# S32K324_M7 register map
Vendor: NXP Semiconductors; File version: 1.1
CPU: CM7 r0p1, little endian, MPU, FPU, VTOR, 4 interrupt priority bits
Registers are 32-bit, read-write, reset 0x0 unless marked. A register's access mark holds for its fields unless they carry their own. Offsets are from the block's base; [hi:lo] are bit positions; {n}, {i} and the like mark numbered series; 'fields as' and 'values as' point back to an identical list.

## CAN_0 — CAN
Base 0x40304000
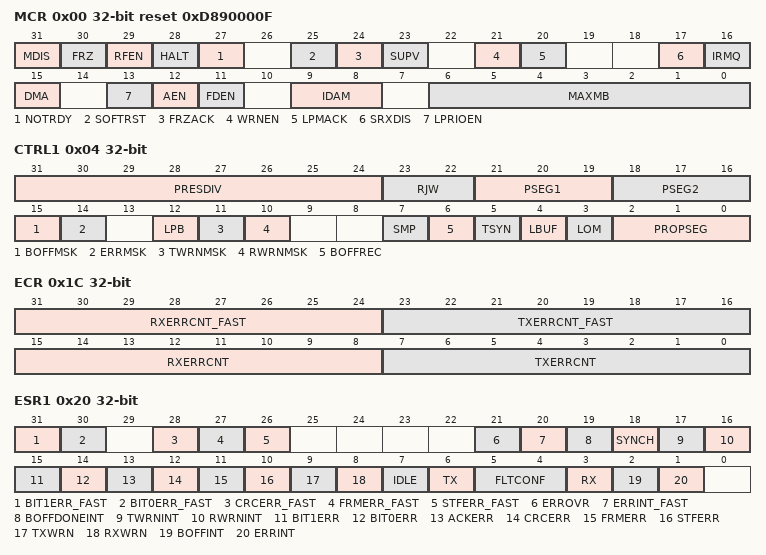
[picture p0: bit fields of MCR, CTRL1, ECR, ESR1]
0x00 MCR reset 0xD890000F — Module Configuration Register
  [31] MDIS — Module Disable
    0=flexcan_enabled (Enable the FlexCAN module.); 1=flexcan_disabled (Disable the FlexCAN module.)
  [30] FRZ — Freeze Enable
    0=freeze_mode_disabled (Not enabled to enter Freeze mode.); 1=freeze_mode_enabled (Enabled to enter Freeze mode.)
  [29] RFEN — Legacy Rx FIFO Enable
    0=id1 (Legacy Rx FIFO not enabled.); 1=id3 (Legacy Rx FIFO enabled.)
  [28] HALT — Halt FlexCAN
    0=HALT_disable (No Freeze mode request.); 1=HALT_enable (Enters Freeze mode if the FRZ bit is asserted.)
  [27] NOTRDY ro — FlexCAN Not Ready
    0=id1 (FlexCAN module is either in Normal mode, Listen-Only mode, or Loop-Back mode.); 1=id5 (FlexCAN module is either in Disable mode or Freeze mode.)
  [25] SOFTRST — Soft Reset
    0=SOFTRST_no_reset_request (No reset request.); 1=SOFTRST_reset_registers (Resets the registers affected by soft reset.)
  [24] FRZACK ro — Freeze Mode Acknowledge
    0=freeze_mode_no (FlexCAN not in Freeze mode, prescaler running.); 1=freeze_mode_yes (FlexCAN in Freeze mode, prescaler stopped.)
  [23] SUPV — Supervisor Mode
    0=id2 (FlexCAN is in User mode. Affected registers allow both Supervisor and Unrestricted accesses.); 1=id4 (FlexCAN is in Supervisor mode. Affected registers allow only Supervisor access. Unrestricted access behaves as though the access was done to an unimplemented register location.)
  [21] WRNEN — Warning Interrupt Enable
    0=TWRNINT_RWRNINT_inactive (TWRNINT and RWRNINT bits are zero, independent of the values in the error counters.); 1=TWRNINT_RWRNINT_active (TWRNINT and RWRNINT bits are set when the respective error counter transitions from less than 96 to greater than or equal to 96.)
  [20] LPMACK ro — Low-Power Mode Acknowledge
    0=low_power_no (FlexCAN is not in a low-power mode.); 1=low_power_yes (FlexCAN is in a low-power mode.)
  [17] SRXDIS — Self Reception Disable
    0=self_reception_enabled; 1=self_reception_disabled
  [16] IRMQ — Individual Rx Masking And Queue Enable
    0=individual_rx_masking_disabled (Individual Rx masking and queue feature are disabled. For backward compatibility with legacy applications, the reading of C/S word locks the MB even if it is EMPTY.); 1=individual_rx_masking_enabled (Individual Rx masking and queue feature are enabled.)
  [15] DMA — DMA Enable
    0=id1 (DMA feature for Legacy RX FIFO or Enhanced Rx FIFO disabled.); 1=id3 (DMA feature for Legacy RX FIFO or Enhanced Rx FIFO enabled.)
  [13] LPRIOEN — Local Priority Enable
    0=local_priority_disabled; 1=local_priority_enabled
  [12] AEN — Abort Enable
    0=abort_disabled; 1=abort_enabled
  [11] FDEN — CAN FD operation enable
    0=CAN_FD_disabled (CAN FD is disabled. FlexCAN is able to receive and transmit messages in CAN 2.0 format.); 1=CAN_FD_enabled (CAN FD is enabled. FlexCAN is able to receive and transmit messages in both CAN FD and CAN 2.0 formats.)
  [9:8] IDAM — ID Acceptance Mode
    0=one_full_ID (Format A: One full ID (standard and extended) per ID filter table element.); 1=two_full_ID (Format B: Two full standard IDs or two partial 14-bit (standard and extended) IDs per ID filter table element.); 2=four_partial_ID (Format C: Four partial 8-bit standard IDs per ID filter table element.); 3=all_frames_rejected (Format D: All frames rejected.)
  [6:0] MAXMB — Number Of The Last Message Buffer
0x04 CTRL1 — Control 1 Register
  [31:24] PRESDIV — Prescaler Division Factor
  [23:22] RJW — Resync Jump Width
  [21:19] PSEG1 — Phase Segment 1
  [18:16] PSEG2 — Phase Segment 2
  [15] BOFFMSK — Bus Off Interrupt Mask
    0=bus_off_int_disabled (Bus Off interrupt disabled.); 1=bus_off_int_enabled (Bus Off interrupt enabled.)
  [14] ERRMSK — Error Interrupt Mask
    0=error_int_disabled (Error interrupt disabled.); 1=error_int_enabled (Error interrupt enabled.)
  [12] LPB — Loop Back Mode
    0=loopback_disabled; 1=loopback_enabled
  [11] TWRNMSK — Tx Warning Interrupt Mask
    0=tx_warning_int_disabled (Tx Warning interrupt disabled.); 1=tx_warning_int_enabled (Tx Warning interrupt enabled.)
  [10] RWRNMSK — Rx Warning Interrupt Mask
    0=rx_warning_int_disabled (Rx Warning interrupt disabled.); 1=rx_warning_int_enabled (Rx Warning interrupt enabled.)
  [7] SMP — CAN Bit Sampling
    0=one_sample (Just one sample is used to determine the bit value.); 1=Three samples are used to determine the value of the received bit: the regular one (sample point) and two preceding samples; a majority rule is used
  [6] BOFFREC — Bus Off Recovery
    0=auto_recover_enabled (Automatic recovering from Bus Off state enabled.); 1=auto_recover_disabled (Automatic recovering from Bus Off state disabled.)
  [5] TSYN — Timer Sync
    0=timer_sync_disabled (Timer sync feature disabled); 1=timer_sync_enabled (Timer sync feature enabled)
  [4] LBUF — Lowest Buffer Transmitted First
    0=highest_buffer_first (Buffer with highest priority is transmitted first.); 1=lowest_buffer_first (Lowest number buffer is transmitted first.)
  [3] LOM — Listen-Only Mode
    0=listen_only_mode_disabled (Listen-Only mode is deactivated.); 1=listen_only_mode_enabled (FlexCAN module operates in Listen-Only mode.)
  [2:0] PROPSEG — Propagation Segment
0x08 TIMER — Free Running Timer
  [15:0] TIMER — Timer Value
0x10 RXMGMASK reset not defined — Rx Mailboxes Global Mask Register
  [31:0] MG — Rx Mailboxes Global Mask Bits
0x14 RX14MASK reset not defined
  [31:0] RX14M — Rx Buffer 14 Mask Bits
0x18 RX15MASK reset not defined
  [31:0] RX15M — Rx Buffer 15 Mask Bits
0x1C ECR — Error Counter
  [31:24] RXERRCNT_FAST — Receive Error Counter for fast bits
  [23:16] TXERRCNT_FAST — Transmit Error Counter for fast bits
  [15:8] RXERRCNT — Receive Error Counter
  [7:0] TXERRCNT — Transmit Error Counter
0x20 ESR1 — Error and Status 1 Register
  [31] BIT1ERR_FAST ro — Bit1 Error in the Data Phase of CAN FD frames with the BRS bit set
    0=bit1_error_no (No such occurrence.); 1=bit1_error_yes (At least one bit sent as recessive is received as dominant.)
  [30] BIT0ERR_FAST ro — Bit0 Error in the Data Phase of CAN FD frames with the BRS bit set
    0=bit0_error_no (No such occurrence.); 1=bit0_error_yes (At least one bit sent as dominant is received as recessive.)
  [28] CRCERR_FAST ro — Cyclic Redundancy Check Error in the CRC field of CAN FD frames with the BRS bit set
    0=CRC_error_no (No such occurrence.); 1=CRC_error_yes (A CRC error occurred since last read of this register.)
  [27] FRMERR_FAST ro — Form Error in the Data Phase of CAN FD frames with the BRS bit set
    0=form_error_no (No such occurrence.); 1=form_error_yes (A form error occurred since last read of this register.)
  [26] STFERR_FAST ro — Stuffing Error in the Data Phase of CAN FD frames with the BRS bit set
    0=stuffing_error_no (No such occurrence.); 1=stuffing_error_yes (A stuffing error occurred since last read of this register.)
  [21] ERROVR write-1-clears — Error Overrun
    0=overrun_not_occurred (Overrun has not occurred.); 1=overrun_occurred (Overrun has occurred.)
  [20] ERRINT_FAST write-1-clears — Error interrupt for errors detected in Data Phase of CAN FD frames with BRS bit set
    0=errors_data_phase_no (No such occurrence.); 1=errors_data_phase_yes (Indicates setting of any error bit detected in the data phase of CAN FD frames with the BRS bit set.)
  [19] BOFFDONEINT write-1-clears — Bus Off Done Interrupt
    0=bus_off_not_done (No such occurrence.); 1=bus_off_done (FlexCAN module has completed Bus Off process.)
  [18] SYNCH ro — CAN Synchronization Status
    0=CAN_bus_sync_no (FlexCAN is not synchronized to the CAN bus.); 1=CAN_bus_sync_yes (FlexCAN is synchronized to the CAN bus.)
  [17] TWRNINT write-1-clears — Tx Warning Interrupt Flag
    0=Tx_warning_int_no (No such occurrence.); 1=Tx_warning_int_yes (The Tx error counter transitioned from less than 96 to greater than or equal to 96.)
  [16] RWRNINT write-1-clears — Rx Warning Interrupt Flag
    0=Rx_warning_int_no (No such occurrence.); 1=Rx_warning_int_yes (The Rx error counter transitioned from less than 96 to greater than or equal to 96.)
  [15] BIT1ERR ro — Bit1 Error
    values as BIT1ERR_FAST
  [14] BIT0ERR ro — Bit0 Error
    values as BIT0ERR_FAST
  [13] ACKERR ro — Acknowledge Error
    0=ACK_error_no (No such occurrence.); 1=ACK_error_yes (An ACK error occurred since last read of this register.)
  [12] CRCERR ro — Cyclic Redundancy Check Error
    values as CRCERR_FAST
  [11] FRMERR ro — Form Error
    0=form_error_no (No such occurrence.); 1=form_error_yes (A Form Error occurred since last read of this register.)
  [10] STFERR ro — Stuffing Error
    values as STFERR_FAST
  [9] TXWRN ro — TX Error Warning
    0=TXERRCNT_LT_96 (No such occurrence.); 1=TXERRCNT_GTE_96 (TXERRCNT is greater than or equal to 96.)
  [8] RXWRN ro — Rx Error Warning
    0=RXERRCNT_LT_96 (No such occurrence.); 1=RXERRCNT_GTE_96 (RXERRCNT is greater than or equal to 96.)
  [7] IDLE ro
    0=can_bus_not_idle (No such occurrence.); 1=can_bus_idle (CAN bus is now IDLE.)
  [6] TX ro — FlexCAN In Transmission
    0=transmit_message_no (FlexCAN is not transmitting a message.); 1=transmit_message_yes (FlexCAN is transmitting a message.)
  [5:4] FLTCONF ro — Fault Confinement State
    0=error_active; 1=error_passive; 0b1x=bus_off
  [3] RX ro — FlexCAN In Reception
    0=DISABLE (FlexCAN is not receiving a message.); 1=ENABLE (FlexCAN is receiving a message.)
  [2] BOFFINT write-1-clears — Bus Off Interrupt
    0=DISABLE (No such occurrence.); 1=ENABLE (FlexCAN module entered Bus Off state.)
  [1] ERRINT write-1-clears — Error Interrupt
    0=DISABLE (No such occurrence.); 1=ENABLE (Indicates setting of any error bit in the Error and Status register.)
0x24 IMASK2 — Interrupt Masks 2 Register
  [31:0] BUF63TO32M — Buffer MBi Mask
0x28 IMASK1 — Interrupt Masks 1 Register
  [31:0] BUF31TO0M — Buffer MBi Mask
0x2C IFLAG2 write-1-clears — Interrupt Flags 2 Register
  [31:0] BUF63TO32I write-1-clears — Buffer MBi Interrupt
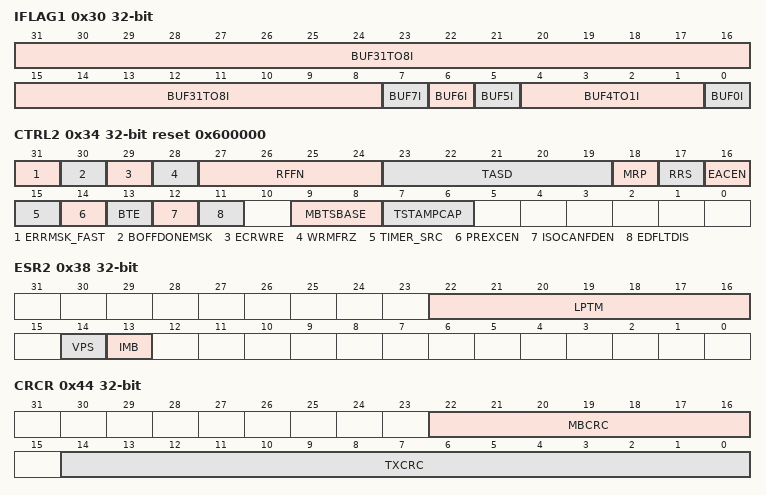
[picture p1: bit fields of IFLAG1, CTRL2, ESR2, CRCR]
0x30 IFLAG1 write-1-clears — Interrupt Flags 1 Register
  [31:8] BUF31TO8I write-1-clears — Buffer MBi Interrupt
  [7] BUF7I write-1-clears — Buffer MB7 Interrupt Or Legacy Rx FIFO Overflow
    0=id1 (No occurrence of MB7 completing transmission/reception when MCR[RFEN]=0, or of Legacy Rx FIFO overflow when MCR[RFEN]=1); 1=id3 (MB7 completed transmission/reception when MCR[RFEN]=0, or Legacy Rx FIFO overflow when MCR[RFEN]=1)
  [6] BUF6I write-1-clears — Buffer MB6 Interrupt Or Legacy Rx FIFO Warning
    0=id1 (No occurrence of MB6 completing transmission/reception when MCR[RFEN]=0, or of Legacy Rx FIFO almost full when MCR[RFEN]=1); 1=id3 (MB6 completed transmission/reception when MCR[RFEN]=0, or Legacy Rx FIFO almost full when MCR[RFEN]=1)
  [5] BUF5I write-1-clears — Buffer MB5 Interrupt Or Frames available in Legacy Rx FIFO
    0=id1 (No occurrence of MB5 completing transmission/reception when MCR[RFEN]=0, or of frame(s) available in the Legacy FIFO, when MCR[RFEN]=1); 1=id3 (MB5 completed transmission/reception when MCR[RFEN]=0, or frame(s) available in the Legacy Rx FIFO when MCR[RFEN]=1. It generates a DMA request in case of MCR[RFEN] and MCR[DMA] are enabled.)
  [4:1] BUF4TO1I write-1-clears — Buffer MBi Interrupt Or Reserved
  [0] BUF0I write-1-clears — Buffer MB0 Interrupt Or Clear Legacy FIFO bit
    0=buffer_Tx_Rx_not_complete (The corresponding buffer has no occurrence of successfully completed transmission or reception when MCR[RFEN]=0.); 1=buffer_Tx_Rx_complete (The corresponding buffer has successfully completed transmission or reception when MCR[RFEN]=0.)
0x34 CTRL2 reset 0x600000 — Control 2 Register
  [31] ERRMSK_FAST — Error Interrupt Mask for errors detected in the data phase of fast CAN FD frames
    0=DISABLE (ERRINT_FAST error interrupt disabled.); 1=ENABLE (ERRINT_FAST error interrupt enabled.)
  [30] BOFFDONEMSK — Bus Off Done Interrupt Mask
    0=DISABLE (Bus off done interrupt disabled.); 1=ENABLE (Bus off done interrupt enabled.)
  [29] ECRWRE — Error-correction Configuration Register Write Enable
    0=DISABLE (Disable update.); 1=ENABLE (Enable update.)
  [28] WRMFRZ — Write-Access To Memory In Freeze Mode
    0=DISABLE (Maintain the write access restrictions.); 1=ENABLE (Enable unrestricted write access to FlexCAN memory.)
  [27:24] RFFN — Number Of Legacy Rx FIFO Filters
  [23:19] TASD — Tx Arbitration Start Delay
  [18] MRP — Mailboxes Reception Priority
    0=id1 (Matching starts from Legacy Rx FIFO or Enhanced Rx FIFO and continues on mailboxes.); 1=id3 (Matching starts from mailboxes and continues on Legacy Rx FIFO or Enhanced Rx FIFO.)
  [17] RRS — Remote Request Storing
    0=remote_response_frame_not_generated (Remote response frame is generated.); 1=remote_response_frame_generated (Remote request frame is stored.)
  [16] EACEN — Entire Frame Arbitration Field Comparison Enable For Rx Mailboxes
    0=RTR_compare_no (Rx mailbox filter's IDE bit is always compared and RTR is never compared despite mask bits.); 1=RTR_compare_yes (Enables the comparison of both Rx mailbox filter's IDE and RTR bit with their corresponding bits within the incoming frame. Mask bits do apply.)
  [15] TIMER_SRC — Timer Source
    0=CAN_bit_clock (The free running timer is clocked by the CAN bit clock, which defines the baud rate on the CAN bus.); 1=external_clock (The free running timer is clocked by an external time tick. The period can be either adjusted to be equal to the baud rate on the CAN bus, or a different value as required. See the device-specific section for details about the external time tick.)
  [14] PREXCEN — Protocol Exception Enable
    0=DISABLE (Protocol exception is disabled.); 1=ENABLE (Protocol exception is enabled.)
  [13] BTE — Bit Timing Expansion enable
    0=DISABLE (CAN Bit timing expansion is disabled.); 1=ENABLE (CAN bit timing expansion is enabled.)
  [12] ISOCANFDEN — ISO CAN FD Enable
    0=non_ISO (FlexCAN operates using the non-ISO CAN FD protocol.); 1=ISO (FlexCAN operates using the ISO CAN FD protocol (ISO 11898-1).)
  [11] EDFLTDIS — Edge Filter Disable
    0=ENABLE (Edge filter is enabled); 1=DISABLE (Edge filter is disabled)
  [9:8] MBTSBASE — Message Buffer Time Stamp Base
    0=base_TIMER (Message buffer time stamp base is TIMER); 1=base_lower_16 (Message buffer time stamp base is lower 16 bits of high resolution timer); 2=base_upper_16 (Message buffer time stamp base is upper 16 bits of high resolution timer)
  [7:6] TSTAMPCAP — Time Stamp Capture Point
    0=time_stamp_capture_disabled (The high resolution time stamp capture is disabled); 1=time_stamp_capture_frame_end_enabled (The high resolution time stamp is captured in the end of the CAN frame); 2=time_stamp_capture_frame_start_enabled (The high resolution time stamp is captured in the start of the CAN frame); 3=time_stamp_capture_2_types_enabled (The high resolution time stamp is captured in the start of frame for classical CAN frames and in res bit for CAN FD frames)
0x38 ESR2 ro — Error and Status 2 Register
  [22:16] LPTM — Lowest Priority Tx Mailbox
  [14] VPS — Valid Priority Status
    0=invalid (Contents of IMB and LPTM are invalid.); 1=valid (Contents of IMB and LPTM are valid.)
  [13] IMB — Inactive Mailbox
    0=inactive_mailbox_no (If ESR2[VPS] is asserted, the ESR2[LPTM] is not an inactive mailbox.); 1=inactive_mailbox_yes (If ESR2[VPS] is asserted, there is at least one inactive mailbox. LPTM content is the number of the first one.)
0x44 CRCR ro — CRC Register
  [22:16] MBCRC — CRC Mailbox
  [14:0] TXCRC — Transmitted CRC value
0x48 RXFGMASK reset not defined — Legacy Rx FIFO Global Mask Register
  [31:0] FGM — Legacy Rx FIFO Global Mask Bits
0x4C RXFIR ro reset not defined — Legacy Rx FIFO Information Register
  [8:0] IDHIT — Identifier Acceptance Filter Hit Indicator
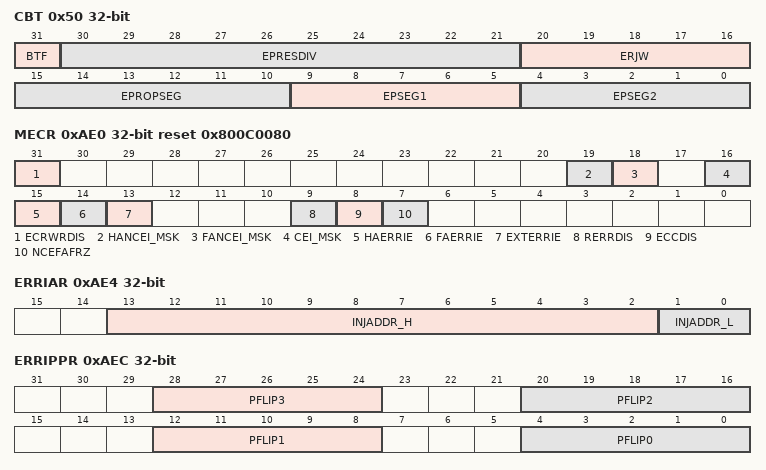
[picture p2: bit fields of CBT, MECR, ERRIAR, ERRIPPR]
0x50 CBT — CAN Bit Timing Register
  [31] BTF — Bit Timing Format Enable
    0=DISABLE (Extended bit time definitions disabled.); 1=ENABLE (Extended bit time definitions enabled.)
  [30:21] EPRESDIV — Extended Prescaler Division Factor
  [20:16] ERJW — Extended Resync Jump Width
  [15:10] EPROPSEG — Extended Propagation Segment
  [9:5] EPSEG1 — Extended Phase Segment 1
  [4:0] EPSEG2 — Extended Phase Segment 2
0x6C IMASK3 — Interrupt Masks 3 Register
  [31:0] BUF95TO64M — Buffer MBi Mask
0x74 IFLAG3 write-1-clears — Interrupt Flags 3 Register
  [31:0] BUF95TO64 write-1-clears — Buffer MBi Interrupt
{0x880+4i} RXIMR[{i}] (i=0..95) reset not defined — Rx Individual Mask Registers
  [31:0] MI — Individual Mask Bits
0xAE0 MECR reset 0x800C0080 — Memory Error Control Register
  [31] ECRWRDIS — Error Configuration Register Write Disable
    0=ENABLE (Write is enabled.); 1=DISABLE (Write is disabled.)
  [19] HANCEI_MSK — Host Access With Non-Correctable Errors Interrupt Mask
    0=DISABLE (Interrupt is disabled.); 1=ENABLE (Interrupt is enabled.)
  [18] FANCEI_MSK — FlexCAN Access With Non-Correctable Errors Interrupt Mask
    values as HANCEI_MSK
  [16] CEI_MSK — Correctable Errors Interrupt Mask
    values as HANCEI_MSK
  [15] HAERRIE — Host Access Error Injection Enable
    0=DISABLE (Injection is disabled.); 1=ENABLE (Injection is enabled.)
  [14] FAERRIE — FlexCAN Access Error Injection Enable
    values as HAERRIE
  [13] EXTERRIE — Extended Error Injection Enable
    0=inject_32_bit (Error injection is applied only to the 32-bit word.); 1=inject_64_bit (Error injection is applied to the 64-bit word.)
  [9] RERRDIS — Error Report Disable
    0=ENABLE (Enable updates of the error report registers.); 1=DISABLE (Disable updates of the error report registers.)
  [8] ECCDIS — Error Correction Disable
    0=ENABLE (Enable memory error correction.); 1=DISABLE (Disable memory error correction.)
  [7] NCEFAFRZ — Non-Correctable Errors In FlexCAN Access Put Device In Freeze Mode
    0=normal (Keep normal operation.); 1=freeze (Put FlexCAN in Freeze mode (see section "Freeze mode").)
0xAE4 ERRIAR — Error Injection Address Register
  [13:2] INJADDR_H — Error Injection Address High
  [1:0] INJADDR_L ro — Error Injection Address Low
0xAE8 ERRIDPR — Error Injection Data Pattern Register
  [31:0] DFLIP — Data flip pattern
0xAEC ERRIPPR — Error Injection Parity Pattern Register
  [28:24] PFLIP3 — Parity Flip Pattern For Byte 3 (most significant)
  [20:16] PFLIP2 — Parity Flip Pattern For Byte 2
  [12:8] PFLIP1 — Parity Flip Pattern For Byte 1
  [4:0] PFLIP0 — Parity Flip Pattern For Byte 0 (Least Significant)
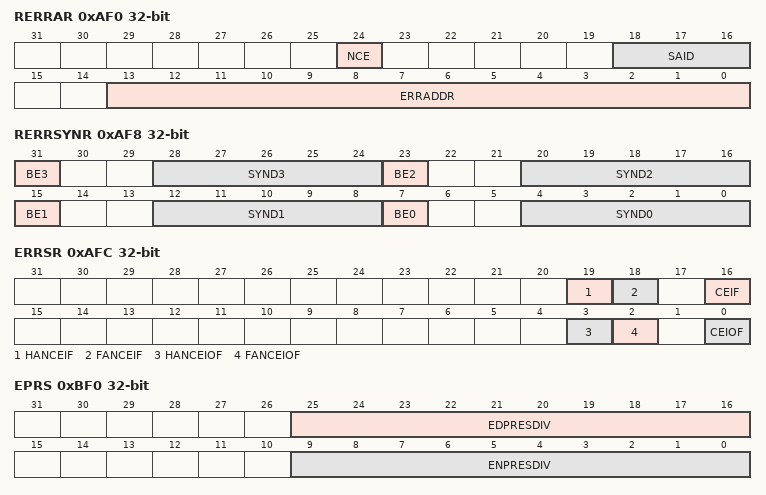
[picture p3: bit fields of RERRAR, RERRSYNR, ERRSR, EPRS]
0xAF0 RERRAR ro — Error Report Address Register
  [24] NCE — Non-Correctable Error
    0=correctable (Reporting a correctable error); 1=non_correctable (Reporting a non-correctable error)
  [18:16] SAID
  [13:0] ERRADDR — Address Where Error Detected
0xAF4 RERRDR ro — Error Report Data Register
  [31:0] RDATA — Raw data word read from memory with error
0xAF8 RERRSYNR ro — Error Report Syndrome Register
  [31] BE3 — Byte Enabled For Byte 3 (most significant)
    0=not_read (The byte was not read.); 1=read (The byte was read.)
  [28:24] SYND3 — Error Syndrome For Byte 3 (most significant)
  [23] BE2 — Byte Enabled For Byte 2
    values as BE3
  [20:16] SYND2 — Error Syndrome For Byte 2
  [15] BE1 — Byte Enabled For Byte 1
    values as BE3
  [12:8] SYND1 — Error Syndrome for Byte 1
  [7] BE0 — Byte Enabled For Byte 0 (least significant)
    values as BE3
  [4:0] SYND0 — Error Syndrome For Byte 0 (least significant)
0xAFC ERRSR write-1-clears — Error Status Register
  [19] HANCEIF write-1-clears — Host Access With Non-Correctable Error Interrupt Flag
    0=not_found (No non-correctable errors were detected in host accesses so far.); 1=found (A non-correctable error was detected in a host access.)
  [18] FANCEIF write-1-clears — FlexCAN Access With Non-Correctable Error Interrupt Flag
    0=not_found (No non-correctable errors were detected in FlexCAN accesses so far.); 1=found (A non-correctable error was detected in a FlexCAN access.)
  [16] CEIF write-1-clears — Correctable Error Interrupt Flag
    0=no_errors (No correctable errors were detected so far.); 1=errors (A correctable error was detected.)
  [3] HANCEIOF write-1-clears — Host Access With Non-Correctable Error Interrupt Overrun Flag
    0=No overrun on non-correctable errors in host access; 1=Overrun on non-correctable errors in host access
  [2] FANCEIOF write-1-clears — FlexCAN Access With Non-Correctable Error Interrupt Overrun Flag
    0=No overrun on non-correctable errors in FlexCAN access; 1=Overrun on non-correctable errors in FlexCAN access
  [0] CEIOF write-1-clears — Correctable Error Interrupt Overrun Flag
    0=No overrun on correctable errors; 1=Overrun on correctable errors
0xBF0 EPRS — Enhanced CAN Bit Timing Prescalers
  [25:16] EDPRESDIV — Extended Data Phase Prescaler Division Factor
  [9:0] ENPRESDIV — Extended Nominal Prescaler Division Factor
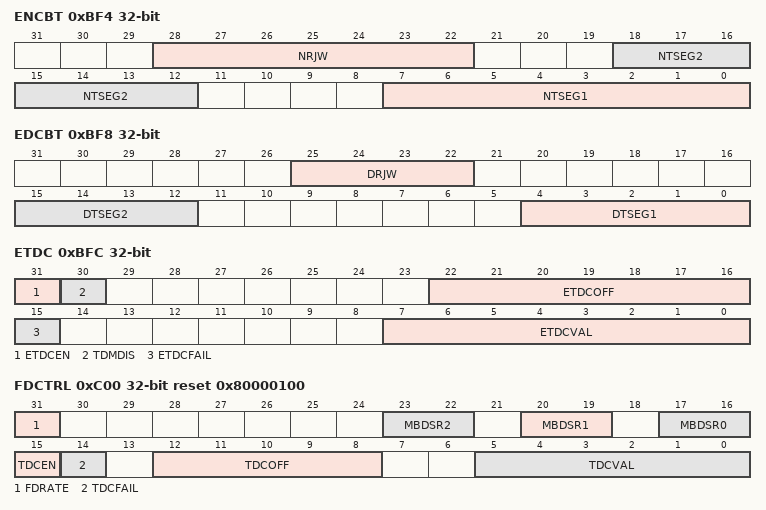
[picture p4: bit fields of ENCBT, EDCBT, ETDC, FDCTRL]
0xBF4 ENCBT — Enhanced Nominal CAN Bit Timing
  [28:22] NRJW — Nominal Resynchronization Jump Width
  [18:12] NTSEG2 — Nominal Time Segment 2
  [7:0] NTSEG1 — Nominal Time Segment 1
0xBF8 EDCBT — Enhanced Data Phase CAN bit Timing
  [25:22] DRJW — Data Phase Resynchronization Jump Width
  [15:12] DTSEG2 — Data Phase Time Segment 2
  [4:0] DTSEG1 — Data Phase Segment 1
0xBFC ETDC — Enhanced Transceiver Delay Compensation
  [31] ETDCEN — Transceiver Delay Compensation Enable
    0=DISABLE (TDC is disabled); 1=ENABLE (TDC is enabled)
  [30] TDMDIS — Transceiver Delay Measurement Disable
    0=ENABLE (TDC measurement is enabled); 1=DISABLE (TDC measurement is disabled)
  [22:16] ETDCOFF — Enhanced Transceiver Delay Compensation Offset
  [15] ETDCFAIL write-1-clears — Transceiver Delay Compensation Fail
    0=in_range (Measured loop delay is in range.); 1=out_of_range (Measured loop delay is out of range.)
  [7:0] ETDCVAL ro — Enhanced Transceiver Delay Compensation Value
0xC00 FDCTRL reset 0x80000100 — CAN FD Control Register
  [31] FDRATE — Bit Rate Switch Enable
    0=nominal (Transmit a frame in nominal rate. The BRS bit in the Tx MB has no effect.); 1=bit_rate_switching (Transmit a frame with bit rate switching if the BRS bit in the Tx MB is recessive.)
  [23:22] MBDSR2 — Message Buffer Data Size for Region 2
    0=R2_8_bytes (Selects 8 bytes per message buffer.); 1=R2_16_bytes (Selects 16 bytes per message buffer.); 2=R2_32_bytes (Selects 32 bytes per message buffer.); 3=R2_64_bytes (Selects 64 bytes per message buffer.)
  [20:19] MBDSR1 — Message Buffer Data Size for Region 1
    0=R1_8_bytes (Selects 8 bytes per message buffer.); 1=R1_16_bytes (Selects 16 bytes per message buffer.); 2=R1_32_bytes (Selects 32 bytes per message buffer.); 3=R1_64_bytes (Selects 64 bytes per message buffer.)
  [17:16] MBDSR0 — Message Buffer Data Size for Region 0
    0=R0_8_bytes (Selects 8 bytes per message buffer.); 1=R0_16_bytes (Selects 16 bytes per message buffer.); 2=R0_32_bytes (Selects 32 bytes per message buffer.); 3=R0_64_bytes (Selects 64 bytes per message buffer.)
  [15] TDCEN — Transceiver Delay Compensation Enable
    0=DISABLE (TDC is disabled); 1=ENABLE (TDC is enabled)
  [14] TDCFAIL write-1-clears — Transceiver Delay Compensation Fail
    values as ETDC.ETDCFAIL
  [12:8] TDCOFF — Transceiver Delay Compensation Offset
  [5:0] TDCVAL ro — Transceiver Delay Compensation Value
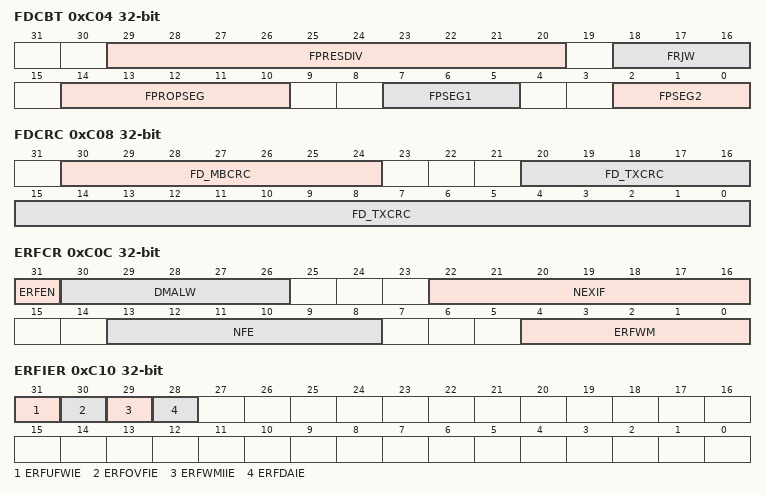
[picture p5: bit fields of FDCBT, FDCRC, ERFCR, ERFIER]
0xC04 FDCBT — CAN FD Bit Timing Register
  [29:20] FPRESDIV — Fast Prescaler Division Factor
  [18:16] FRJW — Fast Resync Jump Width
  [14:10] FPROPSEG — Fast Propagation Segment
  [7:5] FPSEG1 — Fast Phase Segment 1
  [2:0] FPSEG2 — Fast Phase Segment 2
0xC08 FDCRC ro — CAN FD CRC Register
  [30:24] FD_MBCRC — CRC Mailbox Number for FD_TXCRC
  [20:0] FD_TXCRC — Extended Transmitted CRC value
0xC0C ERFCR — Enhanced Rx FIFO Control Register
  [31] ERFEN — Enhanced Rx FIFO enable
    0=DISABLE (Enhanced Rx FIFO is disabled); 1=ENABLE (Enhanced Rx FIFO is enabled)
  [30:26] DMALW — DMA Last Word
  [22:16] NEXIF — Number of Extended ID Filter Elements
  [13:8] NFE — Number of Enhanced Rx FIFO Filter Elements
  [4:0] ERFWM — Enhanced Rx FIFO Watermark
0xC10 ERFIER — Enhanced Rx FIFO Interrupt Enable Register
  [31] ERFUFWIE — Enhanced Rx FIFO Underflow Interrupt Enable
    0=DISABLE (Enhanced Rx FIFO Underflow interrupt is disabled); 1=ENABLE (Enhanced Rx FIFO Underflow interrupt is enabled)
  [30] ERFOVFIE — Enhanced Rx FIFO Overflow Interrupt Enable
    0=DISABLE (Enhanced Rx FIFO Overflow is disabled); 1=ENABLE (Enhanced Rx FIFO Overflow is enabled)
  [29] ERFWMIIE — Enhanced Rx FIFO Watermark Indication Interrupt Enable
    0=DISABLE (Enhanced Rx FIFO Watermark interrupt is disabled); 1=ENABLE (Enhanced Rx FIFO Watermark interrupt is enabled)
  [28] ERFDAIE — Enhanced Rx FIFO Data Available Interrupt Enable
    0=DISABLE (Enhanced Rx FIFO Data Available interrupt is disabled); 1=ENABLE (Enhanced Rx FIFO Data Available interrupt is enabled)
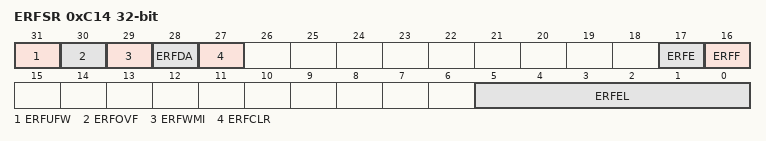
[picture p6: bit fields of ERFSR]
0xC14 ERFSR — Enhanced Rx FIFO Status Register
  [31] ERFUFW write-1-clears — Enhanced Rx FIFO Underflow
    0=no_underflow (No such occurrence); 1=underflow (Enhanced Rx FIFO underflow)
  [30] ERFOVF write-1-clears — Enhanced Rx FIFO Overflow
    0=no_overflow (No such occurrence); 1=overflow (Enhanced Rx FIFO overflow)
  [29] ERFWMI write-1-clears — Enhanced Rx FIFO Watermark Indication
    0=watermark_no (No such occurrence); 1=watermark_yes (The number of messages in FIFO is greater than the watermark)
  [28] ERFDA write-1-clears — Enhanced Rx FIFO Data Available
    0=no_message_stored (No such occurrence); 1=message_stored (There is at least one message stored in Enhanced Rx FIFO)
  [27] ERFCLR — Enhanced Rx FIFO Clear
    0=no_effect; 1=Clear Enhanced Rx FIFO content
  [17] ERFE ro — Enhanced Rx FIFO empty
    0=not_empty (Enhanced Rx FIFO is not empty); 1=empty (Enhanced Rx FIFO is empty)
  [16] ERFF ro — Enhanced Rx FIFO full
    0=not_full (Enhanced Rx FIFO is not full); 1=full (Enhanced Rx FIFO is full)
  [5:0] ERFEL ro — Enhanced Rx FIFO Elements
{0xC30+4i} HR_TIME_STAMP[{i}] (i=0..95) reset not defined — High Resolution Time Stamp
  [31:0] TS
{0x3000+4i} ERFFEL[{i}] (i=0..127) reset not defined — Enhanced Rx FIFO Filter Element
  [31:0] FEL — Filter Element Bits
